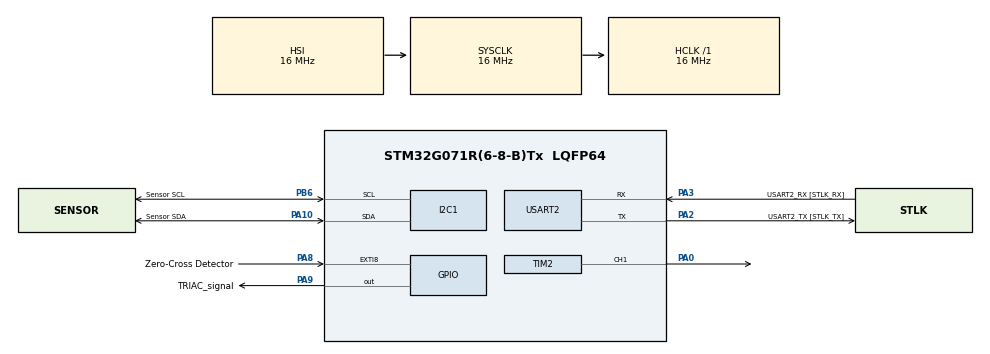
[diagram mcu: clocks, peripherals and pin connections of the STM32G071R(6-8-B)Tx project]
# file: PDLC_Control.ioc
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I2C1.Timing=0x00503D58
Mcu.Family=STM32G0
Mcu.Name=STM32G071R(6-8-B)Tx
Mcu.Package=LQFP64
NVIC.EXTI4_15_IRQn=true\:0\:0\:true\:false\:true\:true\:true\:true
NVIC.TIM3_IRQn=true\:0\:0\:false\:false\:true\:true\:true\:true
PA0.Signal=S_TIM2_CH1_ETR
PA10.GPIO_Label=Sensor SDA
PA10.Mode=I2C
PA10.Signal=I2C1_SDA
PA13.GPIO_Label=TMS
PA13.Signal=SYS_SWDIO
PA14-BOOT0.GPIO_Label=TCK
PA14-BOOT0.Signal=SYS_SWCLK
PA2.GPIO_Label=USART2_TX [STLK_TX]
PA2.Mode=Asynchronous
PA2.Signal=USART2_TX
PA3.GPIO_Label=USART2_RX [STLK_RX]
PA3.Mode=Asynchronous
PA3.Signal=USART2_RX
PA8.GPIO_Label=Zero-Cross Detector
PA8.Signal=GPXTI8
PA9.GPIO_Label=TRIAC_signal
PA9.GPIO_ModeDefaultOutputPP=GPIO_MODE_OUTPUT_PP
PA9.GPIO_PuPd=GPIO_NOPULL
PA9.GPIO_Speed=GPIO_SPEED_FREQ_HIGH
PA9.Signal=GPIO_Output
PB6.GPIO_Label=Sensor SCL
PB6.Mode=I2C
PB6.Signal=I2C1_SCL
PC13.Signal=SYS_WKUP2
PC14-OSC32_IN\ (PC14).Signal=RCC_OSC32_IN
PC15-OSC32_OUT\ (PC15).Signal=RCC_OSC32_OUT
PF0-OSC_IN\ (PF0).GPIO_Label=MCO
PF0-OSC_IN\ (PF0).Signal=RCC_OSC_IN
ProjectManager.HeapSize=0x200
ProjectManager.StackSize=0x400
ProjectManager.TargetToolchain=STM32CubeIDE
RCC.AHBFreq_Value=16000000
RCC.CortexFreq_Value=16000000
RCC.EXTERNAL_CLOCK_VALUE=12288000
RCC.HCLKFreq_Value=16000000
RCC.HSE_VALUE=8000000
RCC.HSI_VALUE=16000000
RCC.LSE_VALUE=32768
RCC.SYSCLKFreq_VALUE=16000000
RCC.VCOOutputFreq_Value=128000000
SH.S_TIM2_CH1_ETR.0=TIM2_CH1,PWM Generation1 CH1
TIM2.AutoReloadPreload=TIM_AUTORELOAD_PRELOAD_ENABLE
TIM2.Channel-PWM\ Generation1\ CH1=TIM_CHANNEL_1
TIM2.Period=1000
TIM3.Period=10100
TIM3.Prescaler=0
USART2.VirtualMode-Asynchronous=VM_ASYNC
VP_TIM2_VS_ClockSourceINT.Mode=Internal
VP_TIM3_VS_ClockSourceINT.Mode=Internal
board=NUCLEO-G071RB

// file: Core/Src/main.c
/* USER CODE BEGIN Header */
/**
  ******************************************************************************
  * @file           : main.c
  * @brief          : Main program body
  ******************************************************************************
  */
/* USER CODE END Header */
#include "main.h"

/* USER CODE BEGIN Includes */
#include <math.h>
#include <stdio.h>
#include <string.h> // Added for UART string parsing (strncmp)
#include "sensor.h"
#include "pdlc_foil.h"
#include "control_algos.h"
/* USER CODE END Includes */

I2C_HandleTypeDef hi2c1;

TIM_HandleTypeDef htim2;
TIM_HandleTypeDef htim3;

UART_HandleTypeDef huart2;

/* USER CODE BEGIN PV */
/* USER CODE BEGIN PV */

// --- BRIDGE TO EXTERNAL MODULES ---
// These tell main.c: "Don't panic! These variables exist in the other .c files!"
extern volatile uint32_t active_delay_us;
extern volatile uint8_t missed_zc_count;
extern volatile uint8_t phase_degrees;

extern volatile float target_rms_voltage;
extern volatile float target_led_brightness;
extern volatile float target_lux;
extern volatile uint8_t system_mode;

// --- LOCAL VARIABLES ---
float last_target_rms = -1.0f;
float last_led_brightness = -1.0f;

extern float master_integral;

// --- UART RECEIVE VARIABLES ---
uint8_t rx_byte;        // Holds the single incoming character
char rx_buffer[20];     // Builds the full message string
uint8_t rx_index = 0;   // Tracks our position in the buffer

/* USER CODE END PV */
/* USER CODE END PV */

void SystemClock_Config(void);
static void MX_GPIO_Init(void);
static void MX_TIM3_Init(void);
static void MX_TIM2_Init(void);
static void MX_I2C1_Init(void);
static void MX_USART2_UART_Init(void);

/* USER CODE BEGIN 0 */
int _write(int file, char *ptr, int len)
{
    HAL_UART_Transmit(&huart2, (uint8_t*)ptr, len, HAL_MAX_DELAY);
    return len;
}

/* USER CODE END 0 */

int main(void)
{
  /* MCU Configuration--------------------------------------------------------*/
  HAL_Init();
  SystemClock_Config();
  MX_GPIO_Init();
  MX_TIM3_Init();
  MX_TIM2_Init();
  MX_I2C1_Init();
  MX_USART2_UART_Init();

  /* USER CODE BEGIN 2 */
  htim3.Instance->PSC = (SystemCoreClock / 1000000) - 1;

  HAL_TIM_Base_Start_IT(&htim3);
  HAL_TIM_OC_Start_IT(&htim3, TIM_CHANNEL_1);

  HAL_TIM_PWM_Start(&htim2, TIM_CHANNEL_1);
  BH1750_Init(&hi2c1);

  HAL_UART_Receive_IT(&huart2, &rx_byte, 1);
  /* USER CODE END 2 */

  /* Infinite loop */
  /* USER CODE BEGIN WHILE */
  while (1)
  {
      if (target_rms_voltage != last_target_rms)
      {
          Update_Angle_From_LUT();
          last_target_rms = target_rms_voltage;
      }

      if (target_led_brightness != last_led_brightness)
      {
          Update_LED_Brightness();
          last_led_brightness = target_led_brightness;
      }

      if (BH1750_Read_NonBlocking(&hi2c1) == 1)
            {
                // A. RUN THE BRAIN
                Calculate_Master_PI_Controller();

                // B. PREPARE THE DECIMAL FOR PRINTING
                int total_tenths = (int)roundf(target_rms_voltage * 10.0f);
                int foil_whole = total_tenths / 10;
                int foil_decimal = total_tenths % 10;

                // C. TALK TO THE PYTHON APP
                printf("{\"lux\": %d, \"target\": %d, \"effort\": %d, \"foil_v\": %d.%d, \"led_pct\": %d}\n",
                      (int)current_lux,
                      (int)target_lux,
                      (int)master_integral,
                      foil_whole, foil_decimal,
                      (int)target_led_brightness);

                // Force the STM32 to flush the UART buffer immediately
                fflush(stdout);

    /* USER CODE END WHILE */
  }
}
}

void SystemClock_Config(void)
{
  RCC_OscInitTypeDef RCC_OscInitStruct = {0};
  RCC_ClkInitTypeDef RCC_ClkInitStruct = {0};

  /** Configure the main internal regulator output voltage
  */
  HAL_PWREx_ControlVoltageScaling(PWR_REGULATOR_VOLTAGE_SCALE1);

  /** Initializes the RCC Oscillators according to the specified parameters
  * in the RCC_OscInitTypeDef structure.
  */
  RCC_OscInitStruct.OscillatorType = RCC_OSCILLATORTYPE_HSI;
  RCC_OscInitStruct.HSIState = RCC_HSI_ON;
  RCC_OscInitStruct.HSIDiv = RCC_HSI_DIV1;
  RCC_OscInitStruct.HSICalibrationValue = RCC_HSICALIBRATION_DEFAULT;
  RCC_OscInitStruct.PLL.PLLState = RCC_PLL_NONE;
  if (HAL_RCC_OscConfig(&RCC_OscInitStruct) != HAL_OK)
  {
    Error_Handler();
  }

  /** Initializes the CPU, AHB and APB buses clocks
  */
  RCC_ClkInitStruct.ClockType = RCC_CLOCKTYPE_HCLK|RCC_CLOCKTYPE_SYSCLK
                              |RCC_CLOCKTYPE_PCLK1;
  RCC_ClkInitStruct.SYSCLKSource = RCC_SYSCLKSOURCE_HSI;
  RCC_ClkInitStruct.AHBCLKDivider = RCC_SYSCLK_DIV1;
  RCC_ClkInitStruct.APB1CLKDivider = RCC_HCLK_DIV1;

  if (HAL_RCC_ClockConfig(&RCC_ClkInitStruct, FLASH_LATENCY_0) != HAL_OK)
  {
    Error_Handler();
  }
}

static void MX_I2C1_Init(void)
{
  hi2c1.Instance = I2C1;
  hi2c1.Init.Timing = 0x00503D58;
  hi2c1.Init.OwnAddress1 = 0;
  hi2c1.Init.AddressingMode = I2C_ADDRESSINGMODE_7BIT;
  hi2c1.Init.DualAddressMode = I2C_DUALADDRESS_DISABLE;
  hi2c1.Init.OwnAddress2 = 0;
  hi2c1.Init.OwnAddress2Masks = I2C_OA2_NOMASK;
  hi2c1.Init.GeneralCallMode = I2C_GENERALCALL_DISABLE;
  hi2c1.Init.NoStretchMode = I2C_NOSTRETCH_DISABLE;
  if (HAL_I2C_Init(&hi2c1) != HAL_OK)
  {
    Error_Handler();
  }

  /** Configure Analogue filter
  */
  if (HAL_I2CEx_ConfigAnalogFilter(&hi2c1, I2C_ANALOGFILTER_ENABLE) != HAL_OK)
  {
    Error_Handler();
  }

  /** Configure Digital filter
  */
  if (HAL_I2CEx_ConfigDigitalFilter(&hi2c1, 0) != HAL_OK)
  {
    Error_Handler();
  }
}

static void MX_TIM2_Init(void)
{
  TIM_ClockConfigTypeDef sClockSourceConfig = {0};
  TIM_MasterConfigTypeDef sMasterConfig = {0};
  TIM_OC_InitTypeDef sConfigOC = {0};

  htim2.Instance = TIM2;
  htim2.Init.Prescaler = 0;
  htim2.Init.CounterMode = TIM_COUNTERMODE_UP;
  htim2.Init.Period = 1000;
  htim2.Init.ClockDivision = TIM_CLOCKDIVISION_DIV1;
  htim2.Init.AutoReloadPreload = TIM_AUTORELOAD_PRELOAD_ENABLE;
  if (HAL_TIM_Base_Init(&htim2) != HAL_OK)
  {
    Error_Handler();
  }
  sClockSourceConfig.ClockSource = TIM_CLOCKSOURCE_INTERNAL;
  if (HAL_TIM_ConfigClockSource(&htim2, &sClockSourceConfig) != HAL_OK)
  {
    Error_Handler();
  }
  if (HAL_TIM_PWM_Init(&htim2) != HAL_OK)
  {
    Error_Handler();
  }
  sMasterConfig.MasterOutputTrigger = TIM_TRGO_RESET;
  sMasterConfig.MasterSlaveMode = TIM_MASTERSLAVEMODE_DISABLE;
  if (HAL_TIMEx_MasterConfigSynchronization(&htim2, &sMasterConfig) != HAL_OK)
  {
    Error_Handler();
  }
  sConfigOC.OCMode = TIM_OCMODE_PWM1;
  sConfigOC.Pulse = 0;
  sConfigOC.OCPolarity = TIM_OCPOLARITY_HIGH;
  sConfigOC.OCFastMode = TIM_OCFAST_DISABLE;
  if (HAL_TIM_PWM_ConfigChannel(&htim2, &sConfigOC, TIM_CHANNEL_1) != HAL_OK)
  {
    Error_Handler();
  }
  HAL_TIM_MspPostInit(&htim2);
}

static void MX_TIM3_Init(void)
{
  TIM_ClockConfigTypeDef sClockSourceConfig = {0};
  TIM_MasterConfigTypeDef sMasterConfig = {0};

  htim3.Instance = TIM3;
  htim3.Init.Prescaler = 0;
  htim3.Init.CounterMode = TIM_COUNTERMODE_UP;
  htim3.Init.Period = 65535;
  htim3.Init.ClockDivision = TIM_CLOCKDIVISION_DIV1;
  htim3.Init.AutoReloadPreload = TIM_AUTORELOAD_PRELOAD_DISABLE;
  if (HAL_TIM_Base_Init(&htim3) != HAL_OK)
  {
    Error_Handler();
  }
  sClockSourceConfig.ClockSource = TIM_CLOCKSOURCE_INTERNAL;
  if (HAL_TIM_ConfigClockSource(&htim3, &sClockSourceConfig) != HAL_OK)
  {
    Error_Handler();
  }
  sMasterConfig.MasterOutputTrigger = TIM_TRGO_RESET;
  sMasterConfig.MasterSlaveMode = TIM_MASTERSLAVEMODE_DISABLE;
  if (HAL_TIMEx_MasterConfigSynchronization(&htim3, &sMasterConfig) != HAL_OK)
  {
    Error_Handler();
  }
}

static void MX_USART2_UART_Init(void)
{
  huart2.Instance = USART2;
  huart2.Init.BaudRate = 115200;
  huart2.Init.WordLength = UART_WORDLENGTH_8B;
  huart2.Init.StopBits = UART_STOPBITS_1;
  huart2.Init.Parity = UART_PARITY_NONE;
  huart2.Init.Mode = UART_MODE_TX_RX;
  huart2.Init.HwFlowCtl = UART_HWCONTROL_NONE;
  huart2.Init.OverSampling = UART_OVERSAMPLING_16;
  huart2.Init.OneBitSampling = UART_ONE_BIT_SAMPLE_DISABLE;
  huart2.Init.ClockPrescaler = UART_PRESCALER_DIV1;
  huart2.AdvancedInit.AdvFeatureInit = UART_ADVFEATURE_NO_INIT;
  if (HAL_UART_Init(&huart2) != HAL_OK)
  {
    Error_Handler();
  }
  if (HAL_UARTEx_SetTxFifoThreshold(&huart2, UART_TXFIFO_THRESHOLD_1_8) != HAL_OK)
  {
    Error_Handler();
  }
  if (HAL_UARTEx_SetRxFifoThreshold(&huart2, UART_RXFIFO_THRESHOLD_1_8) != HAL_OK)
  {
    Error_Handler();
  }
  if (HAL_UARTEx_DisableFifoMode(&huart2) != HAL_OK)
  {
    Error_Handler();
  }
}

static void MX_GPIO_Init(void)
{
  GPIO_InitTypeDef GPIO_InitStruct = {0};

  /* GPIO Ports Clock Enable */
  __HAL_RCC_GPIOC_CLK_ENABLE();
  __HAL_RCC_GPIOF_CLK_ENABLE();
  __HAL_RCC_GPIOA_CLK_ENABLE();
  __HAL_RCC_GPIOB_CLK_ENABLE();

  /*Configure GPIO pin Output Level */
  HAL_GPIO_WritePin(GPIOA, LED_GREEN_Pin|GPIO_PIN_9, GPIO_PIN_RESET);

  /*Configure GPIO pins : LED_GREEN_Pin PA9 */
  GPIO_InitStruct.Pin = LED_GREEN_Pin|GPIO_PIN_9;
  GPIO_InitStruct.Mode = GPIO_MODE_OUTPUT_PP;
  GPIO_InitStruct.Pull = GPIO_NOPULL;
  GPIO_InitStruct.Speed = GPIO_SPEED_FREQ_HIGH;
  HAL_GPIO_Init(GPIOA, &GPIO_InitStruct);

  /*Configure GPIO pin : Zero_Cross_Detector_Pin */
  GPIO_InitStruct.Pin = Zero_Cross_Detector_Pin;
  GPIO_InitStruct.Mode = GPIO_MODE_IT_RISING;
  GPIO_InitStruct.Pull = GPIO_NOPULL;
  HAL_GPIO_Init(Zero_Cross_Detector_GPIO_Port, &GPIO_InitStruct);

  /* EXTI interrupt init*/
  HAL_NVIC_SetPriority(EXTI4_15_IRQn, 0, 0);
  HAL_NVIC_EnableIRQ(EXTI4_15_IRQn);
}

/* USER CODE BEGIN 4 */

void HAL_GPIO_EXTI_Rising_Callback(uint16_t GPIO_Pin)
{
    if(GPIO_Pin == Zero_Cross_Detector_Pin)
    {
        // 1. SOFTWARE FILTER: Check time since last trigger
        static uint32_t last_zcd_time = 0;
        uint32_t current_time = HAL_GetTick();

        // Safe debounce: 3ms ignores noise but leaves a wide window for the 10ms true pulse
        if ((current_time - last_zcd_time) >= 3)
        {
            last_zcd_time = current_time; // Update the timestamp

            // 2. We got a real, filtered zero-cross! Sync the timer to reality.
            __HAL_TIM_SET_COUNTER(&htim3, 0);

            // TIMING FIX: Update the compare register ONLY at zero-cross
            __HAL_TIM_SET_COMPARE(&htim3, TIM_CHANNEL_1, active_delay_us);

            missed_zc_count = 0; // Reset our safety counter
        }
    }
}

void HAL_TIM_PeriodElapsedCallback(TIM_HandleTypeDef *htim)
{
    if(htim->Instance == TIM3)
    {
        // If the timer rolls over naturally, it means the hardware ZCD missed the pulse.
        // We just "predicted" a zero cross!
        missed_zc_count++;

        // Safety cutoff: If we miss more than 3 real zero-crossings in a row,
        // the AC grid power might actually be off.
        if(missed_zc_count > 3)
        {
        	NVIC_SystemReset(); // Force a system reboot
        }
    }
}

void HAL_TIM_OC_DelayElapsedCallback(TIM_HandleTypeDef *htim)
{
    if(htim->Instance == TIM3 && htim->Channel == HAL_TIM_ACTIVE_CHANNEL_1)
    {
        // Only fire if the angle is valid AND we haven't lost grid power (missed <= 3)
        if(phase_degrees < 180 && missed_zc_count <= 3)
        {
            // Execute the 3-pulse train to guarantee latching
            for(int p = 0; p < 3; p++)
            {
                HAL_GPIO_WritePin(GPIOA, GPIO_PIN_9, GPIO_PIN_SET);
                // INTERRUPT FIX: Shrunk from 500 to 50 iterations so UART isn't choked
                for(volatile int i=0; i<50; i++);

                HAL_GPIO_WritePin(GPIOA, GPIO_PIN_9, GPIO_PIN_RESET);
                for(volatile int i=0; i<50; i++);
            }
        }
    }
}

// ORE (OVERRUN ERROR) RECOVERY FIX:
// Automatically restart the UART receiver if bytes crash into each other
void HAL_UART_ErrorCallback(UART_HandleTypeDef *huart)
{
    if (huart->Instance == USART2)
    {
        __HAL_UART_CLEAR_OREFLAG(huart);
        __HAL_UART_CLEAR_NEFLAG(huart);
        __HAL_UART_CLEAR_FEFLAG(huart);
        HAL_UART_Receive_IT(&huart2, &rx_byte, 1);
    }
}

// --- FULL UART COMMAND PARSER ---
// --- FULL UART COMMAND PARSER ---
void HAL_UART_RxCpltCallback(UART_HandleTypeDef *huart)
{
    if (huart->Instance == USART2)
    {
        // If we received an "Enter" key (newline or carriage return)
        if (rx_byte == '\n' || rx_byte == '\r')
        {
            rx_buffer[rx_index] = '\0'; // Cap off the end of the string

            // 1. AUTO MODE COMMAND
            if (strstr(rx_buffer, "AUTO") != NULL) {
                system_mode = 1;
            }
            // 2. MANUAL MODE COMMAND
            else if (strstr(rx_buffer, "MANUAL") != NULL) {
                system_mode = 0;
            }
            // 3. TARGET LUX COMMAND (Forgiving Parser)
                        else if (rx_buffer[0] == 'T' || rx_buffer[0] == 't') {
                            char *colon = strchr(rx_buffer, ':'); // Find where the colon is
                            if (colon != NULL) {
                                int new_target = 0;
                                sscanf(colon + 1, "%d", &new_target); // Read the number after the colon

                                if (new_target >= 0 && new_target <= 2000) {
                                    target_lux = (float)new_target; // <--- FIXED THIS LINE
                                }
                            }
                        }
            // 4. MANUAL LED COMMAND
            else if (strstr(rx_buffer, "LED") != NULL) {
                if (system_mode == 0) {
                    char *colon = strchr(rx_buffer, ':');
                    if (colon != NULL) {
                        int led_val = 0;
                        sscanf(colon + 1, "%d", &led_val);
                        if (led_val >= 0 && led_val <= 100) target_led_brightness = (float)led_val;
                    }
                }
            }
            // 5. MANUAL FOIL COMMAND
            else if (strstr(rx_buffer, "FOIL") != NULL) {
                if (system_mode == 0) {
                    char *colon = strchr(rx_buffer, ':');
                    if (colon != NULL) {
                        int foil_val = 0;
                        sscanf(colon + 1, "%d", &foil_val);
                        if (foil_val >= 0 && foil_val <= 100) Set_Manual_Foil_Pct((float)foil_val);
                    }
                }
            }

            rx_index = 0; // Reset the buffer for the next message
        }
        else
        {
            // If it's a normal character, add it to our string buffer
            if (rx_index < 19)
            {
                rx_buffer[rx_index++] = rx_byte;
            }
            else
            {
                // BUFFER LOCKOUT FIX: Clear the buffer safely if no \n was received
                rx_index = 0;
                memset(rx_buffer, 0, sizeof(rx_buffer));
            }
        }

        // Very Important: Restart the interrupt to listen for the next character!
        HAL_UART_Receive_IT(&huart2, &rx_byte, 1);
    }
}

/* USER CODE END 4 */

void Error_Handler(void)
{
  __disable_irq();
  while (1)
  {
  }
}
